# MSP430FR5739 register map
File version: 1.1
CPU: msp430
Registers are 16-bit, access not given, reset 0x0 unless marked. A register's access mark holds for its fields unless they carry their own. Offsets are from the block's base; [hi:lo] are bit positions; lines under a group give offsets from that group; {n}, {i} and the like mark numbered series.

## Timer1_A3
Base 0x00000000
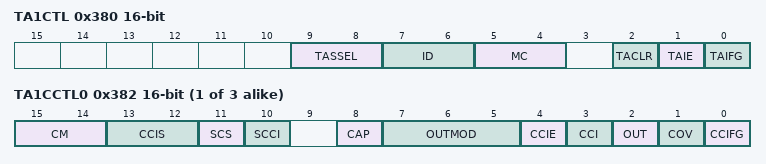
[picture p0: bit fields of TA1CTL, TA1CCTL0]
0x380 TA1CTL — Timer1_A3 Control
  [9:8] TASSEL — [9:8] Timer A clock source select 1
    0=Timer A clock source select: 0 - TACLK; 1=Timer A clock source select: 1 - ACLK; 2=Timer A clock source select: 2 - SMCLK; 3=Timer A clock source select: 3 - INCLK
  [7:6] ID — [7:6] Timer A clock input divider 1
    0=Timer A input divider: 0 - /1; 1=Timer A input divider: 1 - /2; 2=Timer A input divider: 2 - /4; 3=Timer A input divider: 3 - /8
  [5:4] MC — [5:4] Timer A mode control 1
    0=Timer A mode control: 0 - Stop; 1=Timer A mode control: 1 - Up to CCR0; 2=Timer A mode control: 2 - Continuous up; 3=Timer A mode control: 3 - Up/Down
  [2] TACLR — [2:2] Timer A counter clear
  [1] TAIE — [1:1] Timer A counter interrupt enable
  [0] TAIFG — [0:0] Timer A counter interrupt flag
{0x382+2i} TA1CCTL{i} (i=0..2) — Timer1_A3 Capture/Compare Control {i}
  [15:14] CM — [15:14] Capture mode 1
    0=Capture mode: 0 - disabled; 1=Capture mode: 1 - pos. edge; 2=Capture mode: 1 - neg. edge; 3=Capture mode: 1 - both edges
  [13:12] CCIS — [13:12] Capture input select 1
    0=Capture input select: 0 - CCIxA; 1=Capture input select: 1 - CCIxB; 2=Capture input select: 2 - GND; 3=Capture input select: 3 - Vcc
  [11] SCS — [11:11] Capture sychronize
  [10] SCCI — [10:10] Latched capture signal (read)
  [8] CAP — [8:8] Capture mode: 1 /Compare mode : 0
  [7:5] OUTMOD — [7:5] Output mode 2
    0=PWM output mode: 0 - output only; 1=PWM output mode: 1 - set; 2=PWM output mode: 2 - PWM toggle/reset; 3=PWM output mode: 3 - PWM set/reset; 4=PWM output mode: 4 - toggle; 5=PWM output mode: 5 - Reset; 6=PWM output mode: 6 - PWM toggle/set; 7=PWM output mode: 7 - PWM reset/set
  [4] CCIE — [4:4] Capture/compare interrupt enable
  [3] CCI — [3:3] Capture input signal (read)
  [2] OUT — [2:2] PWM Output signal if output mode 0
  [1] COV — [1:1] Capture/compare overflow flag
  [0] CCIFG — [0:0] Capture/compare interrupt flag
0x390 TA1R — Timer1_A3
{0x392+2i} TA1CCR{i} (i=0..2) — Timer1_A3 Capture/Compare {i}
0x3A0 TA1EX0 — Timer1_A3 Expansion Register 0
  [2:0] TAIDEX — [2:0] Timer A Input divider expansion Bit: 0
    {v}=Timer A Input divider expansion : /{v+1} (v=0..7)
0x3AE TA1IV — Timer1_A3 Interrupt Vector Word

## Timer0_B3
Base 0x00000000
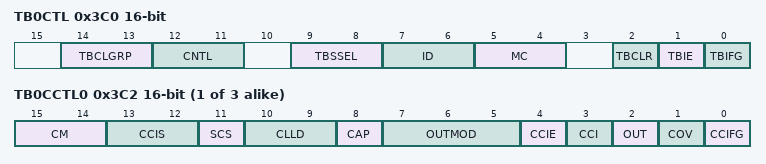
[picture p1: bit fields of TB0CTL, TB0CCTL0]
0x3C0 TB0CTL — Timer0_B7 Control
  [14:13] TBCLGRP — [14:13] Timer0_B7 Compare latch load group 1
    0=Timer0_B7 Group: 0 - individually; 1=Timer0_B7 Group: 1 - 3 groups (1-2; 2=Timer0_B7 Group: 2 - 2 groups (1-3; 3=Timer0_B7 Group: 3 - 1 group (all)
  [12:11] CNTL — [12:11] Counter lenght 1
    0=Counter lenght: 16 bit; 1=Counter lenght: 12 bit; 2=Counter lenght: 10 bit; 3=Counter lenght: 8 bit
  [9:8] TBSSEL — [9:8] Clock source 1
    0=Clock Source: TBCLK; 1=Clock Source: ACLK; 2=Clock Source: SMCLK; 3=Clock Source: INCLK
  [7:6] ID — [7:6] Timer0_B7 clock input divider 1
    0=Timer A input divider: 0 - /1; 1=Timer A input divider: 1 - /2; 2=Timer A input divider: 2 - /4; 3=Timer A input divider: 3 - /8
  [5:4] MC — [5:4] Timer0_B7 mode control 1
    0=Timer A mode control: 0 - Stop; 1=Timer A mode control: 1 - Up to CCR0; 2=Timer A mode control: 2 - Continuous up; 3=Timer A mode control: 3 - Up/Down
  [2] TBCLR — [2:2] Timer0_B7 counter clear
  [1] TBIE — [1:1] Timer0_B7 interrupt enable
  [0] TBIFG — [0:0] Timer0_B7 interrupt flag
{0x3C2+2i} TB0CCTL{i} (i=0..2) — Timer0_B7 Capture/Compare Control {i}
  [15:14] CM — [15:14] Capture mode 1
    0=Capture mode: 0 - disabled; 1=Capture mode: 1 - pos. edge; 2=Capture mode: 1 - neg. edge; 3=Capture mode: 1 - both edges
  [13:12] CCIS — [13:12] Capture input select 1
    0=Capture input select: 0 - CCIxA; 1=Capture input select: 1 - CCIxB; 2=Capture input select: 2 - GND; 3=Capture input select: 3 - Vcc
  [11] SCS — [11:11] Capture sychronize
  [10:9] CLLD — [10:9] Compare latch load source 1
    0=Compare latch load sourec : 0 - immediate; 1=Compare latch load sourec : 1 - TBR counts to 0; 2=Compare latch load sourec : 2 - up/down; 3=Compare latch load sourec : 3 - TBR counts to TBCTL0
  [8] CAP — [8:8] Capture mode: 1 /Compare mode : 0
  [7:5] OUTMOD — [7:5] Output mode 2
    0=PWM output mode: 0 - output only; 1=PWM output mode: 1 - set; 2=PWM output mode: 2 - PWM toggle/reset; 3=PWM output mode: 3 - PWM set/reset; 4=PWM output mode: 4 - toggle; 5=PWM output mode: 5 - Reset; 6=PWM output mode: 6 - PWM toggle/set; 7=PWM output mode: 7 - PWM reset/set
  [4] CCIE — [4:4] Capture/compare interrupt enable
  [3] CCI — [3:3] Capture input signal (read)
  [2] OUT — [2:2] PWM Output signal if output mode 0
  [1] COV — [1:1] Capture/compare overflow flag
  [0] CCIFG — [0:0] Capture/compare interrupt flag
0x3D0 TB0R — Timer0_B7
{0x3D2+2i} TB0CCR{i} (i=0..2) — Timer0_B7 Capture/Compare {i}
0x3E0 TB0EX0 — Timer0_B7 Expansion Register 0
  [2:0] TBIDEX — [2:0] Timer0_B7 Input divider expansion Bit: 0
    {v}=Timer0_B7 Input divider expansion : /{v+1} (v=0..7)
0x3EE TB0IV — Timer0_B7 Interrupt Vector Word
